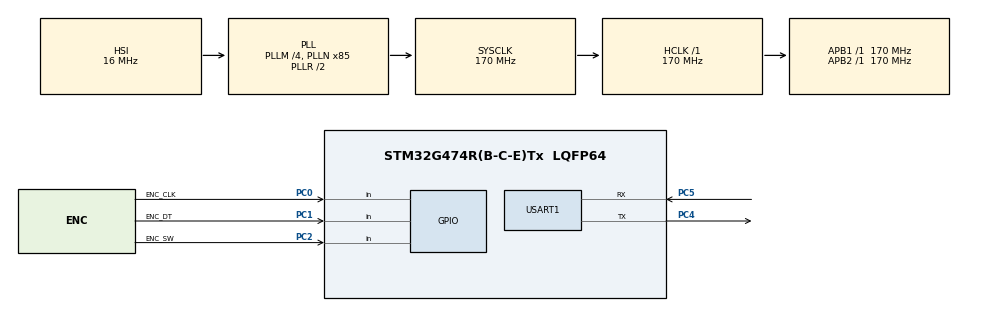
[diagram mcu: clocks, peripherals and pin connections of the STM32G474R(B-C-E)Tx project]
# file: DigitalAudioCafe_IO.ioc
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Dma.Request0=USART1_TX
Dma.Request1=USART1_RX
Dma.USART1_RX.1.Direction=DMA_PERIPH_TO_MEMORY
Dma.USART1_RX.1.EventEnable=DISABLE
Dma.USART1_RX.1.Instance=DMA1_Channel2
Dma.USART1_RX.1.MemDataAlignment=DMA_MDATAALIGN_BYTE
Dma.USART1_RX.1.MemInc=DMA_MINC_ENABLE
Dma.USART1_RX.1.Mode=DMA_NORMAL
Dma.USART1_RX.1.PeriphDataAlignment=DMA_PDATAALIGN_BYTE
Dma.USART1_RX.1.PeriphInc=DMA_PINC_DISABLE
Dma.USART1_RX.1.Polarity=HAL_DMAMUX_REQ_GEN_RISING
Dma.USART1_RX.1.Priority=DMA_PRIORITY_HIGH
Dma.USART1_RX.1.RequestNumber=1
Dma.USART1_RX.1.SignalID=NONE
Dma.USART1_RX.1.SyncEnable=DISABLE
Dma.USART1_RX.1.SyncPolarity=HAL_DMAMUX_SYNC_NO_EVENT
Dma.USART1_RX.1.SyncRequestNumber=1
Dma.USART1_RX.1.SyncSignalID=NONE
Dma.USART1_TX.0.Direction=DMA_MEMORY_TO_PERIPH
Dma.USART1_TX.0.EventEnable=DISABLE
Dma.USART1_TX.0.Instance=DMA1_Channel1
Dma.USART1_TX.0.MemDataAlignment=DMA_MDATAALIGN_BYTE
Dma.USART1_TX.0.MemInc=DMA_MINC_ENABLE
Dma.USART1_TX.0.Mode=DMA_NORMAL
Dma.USART1_TX.0.PeriphDataAlignment=DMA_PDATAALIGN_BYTE
Dma.USART1_TX.0.PeriphInc=DMA_PINC_DISABLE
Dma.USART1_TX.0.Polarity=HAL_DMAMUX_REQ_GEN_RISING
Dma.USART1_TX.0.Priority=DMA_PRIORITY_MEDIUM
Dma.USART1_TX.0.RequestNumber=1
Dma.USART1_TX.0.SignalID=NONE
Dma.USART1_TX.0.SyncEnable=DISABLE
Dma.USART1_TX.0.SyncPolarity=HAL_DMAMUX_SYNC_NO_EVENT
Dma.USART1_TX.0.SyncRequestNumber=1
Dma.USART1_TX.0.SyncSignalID=NONE
Mcu.Family=STM32G4
Mcu.Name=STM32G474R(B-C-E)Tx
Mcu.Package=LQFP64
NUCLEO-G474RE.BUTTON=1
NUCLEO-G474RE.LD2=true
NUCLEO-G474RE.VCP=true
NVIC.DMA1_Channel1_IRQn=true\:0\:0\:false\:false\:true\:false\:true\:true
NVIC.DMA1_Channel2_IRQn=true\:0\:0\:false\:false\:true\:false\:true\:true
NVIC.EXTI15_10_IRQn=true\:0\:0\:false\:false\:true\:false\:true\:true
NVIC.PriorityGroup=NVIC_PRIORITYGROUP_4
NVIC.USART1_IRQn=true\:0\:0\:false\:false\:true\:true\:true\:true
PA13.GPIO_Label=T_SWDIO
PA13.Signal=SYS_JTMS-SWDIO
PA14.GPIO_Label=T_SWCLK
PA14.Signal=SYS_JTCK-SWCLK
PB3.GPIO_Label=T_SWO
PB3.Signal=SYS_JTDO-SWO
PC0.GPIO_Label=ENC_CLK
PC0.GPIO_PuPd=GPIO_PULLUP
PC0.Signal=GPIO_Input
PC1.GPIO_Label=ENC_DT
PC1.GPIO_PuPd=GPIO_PULLUP
PC1.Signal=GPIO_Input
PC14-OSC32_IN.GPIO_Label=RCC_OSC32_IN
PC14-OSC32_IN.Signal=RCC_OSC32_IN
PC15-OSC32_OUT.GPIO_Label=RCC_OSC32_OUT
PC15-OSC32_OUT.Signal=RCC_OSC32_OUT
PC2.GPIO_Label=ENC_SW
PC2.GPIO_PuPd=GPIO_PULLUP
PC2.Signal=GPIO_Input
PC4.Mode=Asynchronous
PC4.Signal=USART1_TX
PC5.Mode=Asynchronous
PC5.Signal=USART1_RX
PF0-OSC_IN.GPIO_Label=RCC_OSC_IN
PF0-OSC_IN.Signal=RCC_OSC_IN
PF1-OSC_OUT.GPIO_Label=RCC_OSC_OUT
PF1-OSC_OUT.Signal=RCC_OSC_OUT
ProjectManager.HeapSize=0x200
ProjectManager.StackSize=0x400
ProjectManager.TargetToolchain=STM32CubeIDE
RCC.ADC12Freq_Value=170000000
RCC.ADC345Freq_Value=170000000
RCC.AHBFreq_Value=170000000
RCC.APB1Freq_Value=170000000
RCC.APB1TimFreq_Value=170000000
RCC.APB2Freq_Value=170000000
RCC.APB2TimFreq_Value=170000000
RCC.CortexFreq_Value=170000000
RCC.EXTERNAL_CLOCK_VALUE=12288000
RCC.HCLKFreq_Value=170000000
RCC.HSE_VALUE=24000000
RCC.HSI48_VALUE=48000000
RCC.HSI_VALUE=16000000
RCC.LSE_VALUE=32768
RCC.PLLM=RCC_PLLM_DIV4
RCC.PLLN=85
RCC.RTCClockSelection=RCC_RTCCLKSOURCE_LSE
RCC.SYSCLKFreq_VALUE=170000000
RCC.SYSCLKSource=RCC_SYSCLKSOURCE_PLLCLK
RCC.USBFreq_Value=170000000
RCC.VCOOutputFreq_Value=340000000
USART1.VirtualMode-Asynchronous=VM_ASYNC
VP_NUCLEO-G474RE_VS_BSP_COMMON.Mode=COMMON
VP_SYS_VS_DBSignals.Mode=DisableDeadBatterySignals
board=NUCLEO-G474RE

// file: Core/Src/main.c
/* USER CODE BEGIN Header */
/**
  ******************************************************************************
  * @file           : main.c
  * @brief          : Main program body
  ******************************************************************************
  * @attention
  *
  * Copyright (c) 2026 STMicroelectronics.
  * All rights reserved.
  *
  * This software is licensed under terms that can be found in the LICENSE file
  * in the root directory of this software component.
  * If no LICENSE file comes with this software, it is provided AS-IS.
  *
  ******************************************************************************
  */
/* USER CODE END Header */
#include "main.h"

COM_InitTypeDef BspCOMInit;
UART_HandleTypeDef huart1;
DMA_HandleTypeDef hdma_usart1_tx;
DMA_HandleTypeDef hdma_usart1_rx;

void SystemClock_Config(void);
static void MX_GPIO_Init(void);
static void MX_DMA_Init(void);
static void MX_USART1_UART_Init(void);

int main(void)
{

  /* MCU Configuration--------------------------------------------------------*/

  /* Reset of all peripherals, Initializes the Flash interface and the Systick. */
  HAL_Init();

  /* Configure the system clock */
  SystemClock_Config();

  /* Initialize all configured peripherals */
  MX_GPIO_Init();
  MX_DMA_Init();
  MX_USART1_UART_Init();
  /* USER CODE BEGIN 2 */
  void app_main(); // Points to wrapper
  app_main(); // Begin!
  /* USER CODE END 2 */

  /* Initialize led */
  BSP_LED_Init(LED_GREEN);

  /* Initialize USER push-button, will be used to trigger an interrupt each time it's pressed.*/
  BSP_PB_Init(BUTTON_USER, BUTTON_MODE_EXTI);

  /* Initialize COM1 port (115200, 8 bits (7-bit data + 1 stop bit), no parity */
  BspCOMInit.BaudRate   = 115200;
  BspCOMInit.WordLength = COM_WORDLENGTH_8B;
  BspCOMInit.StopBits   = COM_STOPBITS_1;
  BspCOMInit.Parity     = COM_PARITY_NONE;
  BspCOMInit.HwFlowCtl  = COM_HWCONTROL_NONE;
  if (BSP_COM_Init(COM1, &BspCOMInit) != BSP_ERROR_NONE)
  {
    Error_Handler();
  }

  /* Infinite loop */
  while (1)
  {

  }
}

void SystemClock_Config(void)
{
  RCC_OscInitTypeDef RCC_OscInitStruct = {0};
  RCC_ClkInitTypeDef RCC_ClkInitStruct = {0};

  /** Configure the main internal regulator output voltage
  */
  HAL_PWREx_ControlVoltageScaling(PWR_REGULATOR_VOLTAGE_SCALE1_BOOST);

  /** Initializes the RCC Oscillators according to the specified parameters
  * in the RCC_OscInitTypeDef structure.
  */
  RCC_OscInitStruct.OscillatorType = RCC_OSCILLATORTYPE_HSI;
  RCC_OscInitStruct.HSIState = RCC_HSI_ON;
  RCC_OscInitStruct.HSICalibrationValue = RCC_HSICALIBRATION_DEFAULT;
  RCC_OscInitStruct.PLL.PLLState = RCC_PLL_ON;
  RCC_OscInitStruct.PLL.PLLSource = RCC_PLLSOURCE_HSI;
  RCC_OscInitStruct.PLL.PLLM = RCC_PLLM_DIV4;
  RCC_OscInitStruct.PLL.PLLN = 85;
  RCC_OscInitStruct.PLL.PLLP = RCC_PLLP_DIV2;
  RCC_OscInitStruct.PLL.PLLQ = RCC_PLLQ_DIV2;
  RCC_OscInitStruct.PLL.PLLR = RCC_PLLR_DIV2;
  if (HAL_RCC_OscConfig(&RCC_OscInitStruct) != HAL_OK)
  {
    Error_Handler();
  }

  /** Initializes the CPU, AHB and APB buses clocks
  */
  RCC_ClkInitStruct.ClockType = RCC_CLOCKTYPE_HCLK|RCC_CLOCKTYPE_SYSCLK
                              |RCC_CLOCKTYPE_PCLK1|RCC_CLOCKTYPE_PCLK2;
  RCC_ClkInitStruct.SYSCLKSource = RCC_SYSCLKSOURCE_PLLCLK;
  RCC_ClkInitStruct.AHBCLKDivider = RCC_SYSCLK_DIV1;
  RCC_ClkInitStruct.APB1CLKDivider = RCC_HCLK_DIV1;
  RCC_ClkInitStruct.APB2CLKDivider = RCC_HCLK_DIV1;

  if (HAL_RCC_ClockConfig(&RCC_ClkInitStruct, FLASH_LATENCY_4) != HAL_OK)
  {
    Error_Handler();
  }
}

static void MX_USART1_UART_Init(void)
{

  huart1.Instance = USART1;
  huart1.Init.BaudRate = 115200;
  huart1.Init.WordLength = UART_WORDLENGTH_8B;
  huart1.Init.StopBits = UART_STOPBITS_1;
  huart1.Init.Parity = UART_PARITY_NONE;
  huart1.Init.Mode = UART_MODE_TX_RX;
  huart1.Init.HwFlowCtl = UART_HWCONTROL_NONE;
  huart1.Init.OverSampling = UART_OVERSAMPLING_16;
  huart1.Init.OneBitSampling = UART_ONE_BIT_SAMPLE_DISABLE;
  huart1.Init.ClockPrescaler = UART_PRESCALER_DIV1;
  huart1.AdvancedInit.AdvFeatureInit = UART_ADVFEATURE_NO_INIT;
  if (HAL_UART_Init(&huart1) != HAL_OK)
  {
    Error_Handler();
  }
  if (HAL_UARTEx_SetTxFifoThreshold(&huart1, UART_TXFIFO_THRESHOLD_1_8) != HAL_OK)
  {
    Error_Handler();
  }
  if (HAL_UARTEx_SetRxFifoThreshold(&huart1, UART_RXFIFO_THRESHOLD_1_8) != HAL_OK)
  {
    Error_Handler();
  }
  if (HAL_UARTEx_DisableFifoMode(&huart1) != HAL_OK)
  {
    Error_Handler();
  }

}

static void MX_DMA_Init(void)
{

  /* DMA controller clock enable */
  __HAL_RCC_DMAMUX1_CLK_ENABLE();
  __HAL_RCC_DMA1_CLK_ENABLE();

  /* DMA interrupt init */
  /* DMA1_Channel1_IRQn interrupt configuration */
  HAL_NVIC_SetPriority(DMA1_Channel1_IRQn, 0, 0);
  HAL_NVIC_EnableIRQ(DMA1_Channel1_IRQn);
  /* DMA1_Channel2_IRQn interrupt configuration */
  HAL_NVIC_SetPriority(DMA1_Channel2_IRQn, 0, 0);
  HAL_NVIC_EnableIRQ(DMA1_Channel2_IRQn);

}

static void MX_GPIO_Init(void)
{
  GPIO_InitTypeDef GPIO_InitStruct = {0};

  /* GPIO Ports Clock Enable */
  __HAL_RCC_GPIOC_CLK_ENABLE();
  __HAL_RCC_GPIOF_CLK_ENABLE();
  __HAL_RCC_GPIOA_CLK_ENABLE();
  __HAL_RCC_GPIOB_CLK_ENABLE();

  /*Configure GPIO pins : ENC_CLK_Pin ENC_DT_Pin ENC_SW_Pin */
  GPIO_InitStruct.Pin = ENC_CLK_Pin|ENC_DT_Pin|ENC_SW_Pin;
  GPIO_InitStruct.Mode = GPIO_MODE_INPUT;
  GPIO_InitStruct.Pull = GPIO_PULLUP;
  HAL_GPIO_Init(GPIOC, &GPIO_InitStruct);

}

void Error_Handler(void)
{
  __disable_irq();
  while (1)
  {
  }
}
